# RS14100 register map
File version: 1.0
CPU: CM4 r0p1, little endian, MPU, FPU, 4 interrupt priority bits
Registers are 32-bit, read-write, reset 0x0 unless marked. A register's access mark holds for its fields unless they carry their own. Offsets are from the block's base; [hi:lo] are bit positions.

## IID_QK — The purpose of Quiddikey is to provide secure key storage without storing the key.
Base 0x20480600
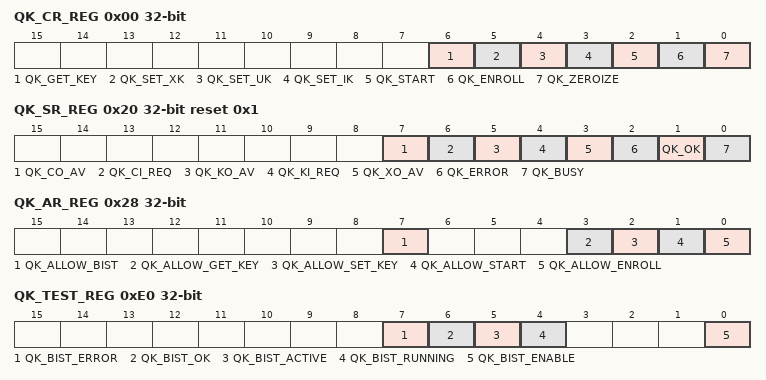
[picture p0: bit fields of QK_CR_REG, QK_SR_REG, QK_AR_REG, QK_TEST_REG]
0x00 QK_CR_REG wo — Quiddikey Control register.The Quiddikey Control register defines which command must be executed next.
  [6] QK_GET_KEY — Begin Get Key operation
  [5] QK_SET_XK — Begin Set External Key operation
  [4] QK_SET_UK — Begin Set User Key operation
  [3] QK_SET_IK — Begin Set Intrinsic Key operation
  [2] QK_START — Begin Start operation
  [1] QK_ENROLL — Begin Enroll operation
  [0] QK_ZEROIZE — Begin Zeroize operation and go to Error state
0x04 QK_KIDX_REG — The Quiddikey Key Index register defines the key index for the next set_key command
  [3:0] QK_KEY_INDEX — Key index for Set Key operations
0x08 QK_KSZ_REG — Quiddikey Key Size register
  [5:0] QK_KEY_SIZE — Key size for Set Key operations
0x0C QK_KT_REG — Quiddikey Key Size register
  [0] QK_KEY_TARGET — Target of reconstructed key
0x20 QK_SR_REG ro reset 0x1 — Quiddikey Status register
  [7] QK_CO_AV — Next part of AC/KC is available
  [6] QK_CI_REQ — Request for next part of AC/KC
  [5] QK_KO_AV — Next part of key is available
  [4] QK_KI_REQ — Request for next part of key
  [3] QK_XO_AV — Next part of XKPD is available
  [2] QK_ERROR — Quiddikey is in the Error state and no operations can be performed
  [1] QK_OK — Last operation was successful
  [0] QK_BUSY — Indicates that operation is in progress
0x28 QK_AR_REG ro — Quiddikey allow register
  [7] QK_ALLOW_BIST — BIST is allowed to be started
  [3] QK_ALLOW_GET_KEY — Get Key operation is allowed
  [2] QK_ALLOW_SET_KEY — Set Key operations are allowed
  [1] QK_ALLOW_START — Start operation is allowed
  [0] QK_ALLOW_ENROLL — Enroll operation is allowed
0x40 QK_KI_REG wo — Quiddikey Key Input register
  [31:0] QK_KI — Key input data
0x44 QK_CI_REG wo — Quiddikey Code Input register
  [31:0] QK_CI — AC/KC input data
0x48 QK_CO_REG ro — Quiddikey Code Output register
  [31:0] QK_CO — AC/KC output data
0x4C QK_XO_REG ro — Quiddikey XKPD Output register
  [31:0] QK_XO — XKPD output data
0x60 QK_KO_IDX_REG ro — Quiddikey Key Output Index register
  [3:0] qk_ko_index — Key index for the key that is currently output via the Key Output register
0x64 QK_KO_REG ro — Quiddikey Code Output register
  [31:0] QK_KO — Key output data
0xDC QK_IF_SR_REG ro — Quiddikey Interface Status register
  [0] IF_ERROR — Indicates that an interface error has occurred
0xDC QK_IF_SR_C_REG ro (alternate view of QK_IF_SR_REG) — Quiddikey Interface Status register
  [0] IF_ERROR — Clears the if_error bit
0xE0 QK_TEST_REG — QK Test register
  [7] QK_BIST_ERROR — Indicates that the BIST has failed
  [6] QK_BIST_OK — Indicates that the BIST has passed
  [5] QK_BIST_ACTIVE — Indicates that the BIST is running
  [4] QK_BIST_RUNNING — BIST is in progress or finishing up
  [0] QK_BIST_ENABLE — Isolates the iid_quiddikey module and runs a BIST
0xFC QK_VER_REG ro — QK Version register
  [31:0] QK_VERSION — Version of iid_qk

## IID_RPINE
Base 0x20480400
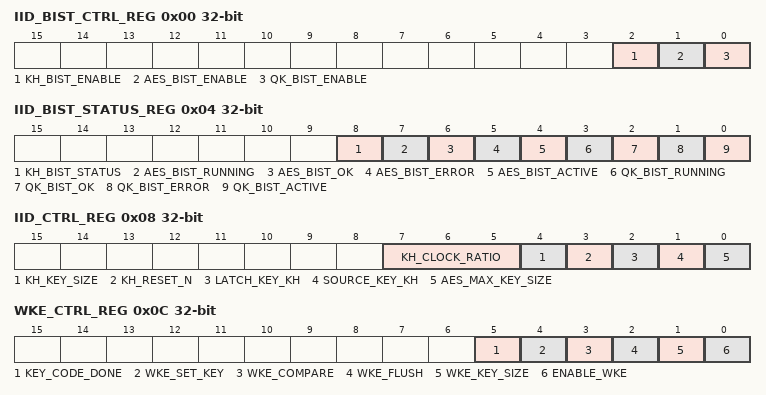
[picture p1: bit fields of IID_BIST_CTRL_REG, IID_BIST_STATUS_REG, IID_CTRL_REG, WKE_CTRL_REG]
0x00 IID_BIST_CTRL_REG — Quiddikey Control register.The Quiddikey Control register defines which command must be executed next.
  [2] KH_BIST_ENABLE, [1] AES_BIST_ENABLE, [0] QK_BIST_ENABLE
0x04 IID_BIST_STATUS_REG
  [8] KH_BIST_STATUS
  [7] AES_BIST_RUNNING — Indicates that the BIST is running
  [6] AES_BIST_OK — Indicates that the BIST has passed
  [5] AES_BIST_ERROR
  [4] AES_BIST_ACTIVE
  [3] QK_BIST_RUNNING — Indicates that the BIST is running
  [2] QK_BIST_OK — Indicates that the BIST has passed
  [1] QK_BIST_ERROR — Indicates that the BIST has failed
  [0] QK_BIST_ACTIVE
0x08 IID_CTRL_REG
  [7:5] KH_CLOCK_RATIO — Indicates the division factor to be used for generating kh_clk.
  [4] KH_KEY_SIZE — 0 128 bit key 1 256 bit key This is used by KH
  [3] KH_RESET_N — 0 KH will be in reset 1 Out of reset
  [2] LATCH_KEY_KH — When set KH will latch the key given by QK. When this is not QK key output is connected to AES key input
  [1] SOURCE_KEY_KH — When set KH will source the key to AES engine. When this is not QK key output is connected to AES key input
  [0] AES_MAX_KEY_SIZE — 1 256 bit key, 0 128 bit key
0x0C WKE_CTRL_REG
  [5] KEY_CODE_DONE — This has to be set after reading key code
  [4] WKE_SET_KEY — This has to be set after key available from AES
  [3] WKE_COMPARE — When set, WKE will compare the data from AES engine with the data provided by firmware
  [2] WKE_FLUSH — When set, WKE will flush out the data from AES. When WEK is active, firmware reads to AES engine are masked. This gets cleared once four dwords are read from AES
  [1] WKE_KEY_SIZE — 0 128 bit size 1 256 bit size
  [0] ENABLE_WKE — When WKE will be enabled. This is a self clearing bit. Once enabled WKE can not be disabled till process is done
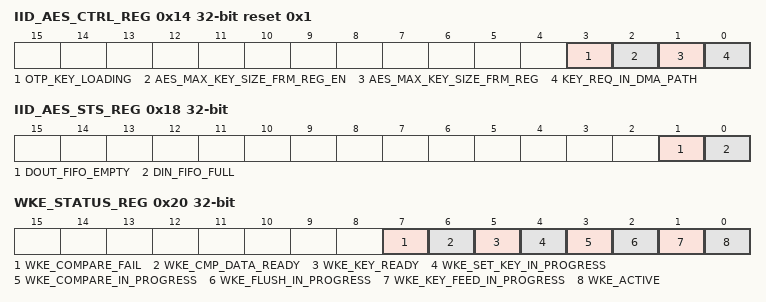
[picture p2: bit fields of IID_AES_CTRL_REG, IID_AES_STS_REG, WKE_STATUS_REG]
0x14 IID_AES_CTRL_REG reset 0x1
  [3] OTP_KEY_LOADING — When set, WKE will compare the data from AES engine with the data provided by firmware
    1=Enable (Loads the OTP Key into the AES Engine, before setting this bit, key should be read from the OTP by reading the otp registers, more information please refer the otp section); 0=Disable (OTP Key will not be loaded)
  [2] AES_MAX_KEY_SIZE_FRM_REG_EN — When set, WKE will flush out the data from AES. When WEK is active, firmware reads to AES engine are masked. This gets cleared once four dwords are read from AES
    1=Enable (AES bit length prog enable.); 0=Disable (AES bit length prog disable.)
  [1] AES_MAX_KEY_SIZE_FRM_REG — This is valid only when aes_max_key_size_frm_reg_en is set.
  [0] KEY_REQ_IN_DMA_PATH — Include key req in dma path. With this KEY Also can be loaded using DMA.
0x18 IID_AES_STS_REG ro
  [1] DOUT_FIFO_EMPTY — Output data fifo empty indication
  [0] DIN_FIFO_FULL — Input data fifo full indication
0x20 WKE_STATUS_REG
  [7] WKE_COMPARE_FAIL — This bit will be set when authentication data comparison fails
  [6] WKE_CMP_DATA_READY — Firmware has to load the authentication, which will be compared with AES output, when this bit is low
  [5] WKE_KEY_READY — Firmware has to load the authentication, which will be compared with AES output, when this bit is low
  [4] WKE_SET_KEY_IN_PROGRESS — Will be high when WKE is doing set key operation with QK
  [3] WKE_COMPARE_IN_PROGRESS — Will be high when WKE is comparing the data from AES
  [2] WKE_FLUSH_IN_PROGRESS — Will be high when WKE flushing out the data from AES
  [1] WKE_KEY_FEED_IN_PROGRESS — Will be high when WKE is feeding key to AES engine
  [0] WKE_ACTIVE — Will be high when WKE is active
0x28 WKE_DATA_REG
